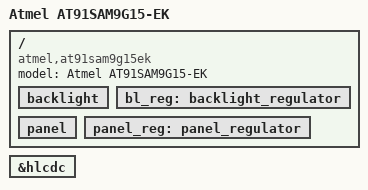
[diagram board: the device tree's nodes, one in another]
/* bench 11740.1.0 cc5e251a1793 */
// SPDX-License-Identifier: GPL-2.0-or-later
/*
 * at91sam9g15ek.dts - Device Tree file for AT91SAM9G15-EK board
 *
 *  Copyright (C) 2012 Atmel,
 *                2012 Nicolas Ferre <nicolas.ferre@atmel.com>
 */
/dts-v1/;
#include "at91sam9g15.dtsi"
#include "at91sam9x5dm.dtsi"
#include "at91sam9x5ek.dtsi"

/ {
	model = "Atmel AT91SAM9G15-EK";
	compatible = "atmel,at91sam9g15ek", "atmel,at91sam9x5ek", "atmel,at91sam9x5", "atmel,at91sam9";

	backlight: backlight {
		status = "okay";
	};

	bl_reg: backlight_regulator {
		status = "okay";
	};

	panel: panel {
		status = "okay";
	};

	panel_reg: panel_regulator {
		status = "okay";
	};
};

&hlcdc {
	status = "okay";
};
/* bench 13785.0.0 e79d7e992fa0 */
/* bench 13785.0.1 462062111fb2 */
/* bench 13785.0.2 e036bd23c90b */
/* bench 13785.0.3 60b2cdf37c26 */
/* bench 13785.0.4 e6f821e4ce65 */
/* bench 13785.0.5 a40e121c1ca5 */
/* bench 13785.0.6 21e8b34c8b40 */
/* bench 13785.0.7 840b2c7dab39 */
/* bench 13785.0.8 0ea508067acd */
/* bench 13785.0.9 0caad2e37f20 */
/* bench 13785.0.10 1cb086d0867b */
/* bench 13785.0.11 cbc35a73e9fd */
